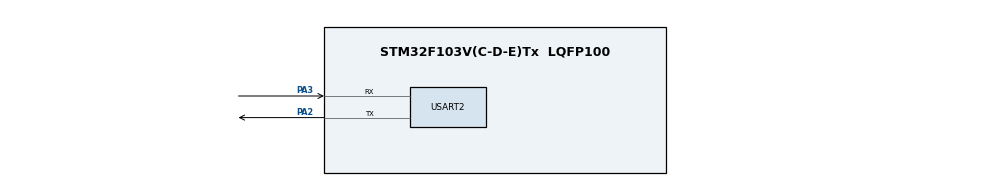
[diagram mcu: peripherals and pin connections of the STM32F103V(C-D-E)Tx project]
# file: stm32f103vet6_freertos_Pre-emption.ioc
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FREERTOS.Tasks01=defaultTask,24,128,StartDefaultTask,Default,NULL,Dynamic,NULL,NULL;LowTask,8,256,StartLowTask,Default,NULL,Dynamic,NULL,NULL;HighTask,40,256,StartHighTask,Default,NULL,Dynamic,NULL,NULL
Mcu.Family=STM32F1
Mcu.Name=STM32F103V(C-D-E)Tx
Mcu.Package=LQFP100
NVIC.PriorityGroup=NVIC_PRIORITYGROUP_4
OSC_IN.Mode=HSE-External-Oscillator
OSC_IN.Signal=RCC_OSC_IN
OSC_OUT.Mode=HSE-External-Oscillator
OSC_OUT.Signal=RCC_OSC_OUT
PA13.Mode=Serial_Wire
PA13.Signal=SYS_JTMS-SWDIO
PA14.Mode=Serial_Wire
PA14.Signal=SYS_JTCK-SWCLK
PA2.Mode=Asynchronous
PA2.Signal=USART2_TX
PA3.Mode=Asynchronous
PA3.Signal=USART2_RX
ProjectManager.HeapSize=0x200
ProjectManager.StackSize=0x400
ProjectManager.TargetToolchain=STM32CubeIDE
RCC.APB1Freq_Value=8000000
RCC.APB2Freq_Value=8000000
USART2.VirtualMode=VM_ASYNC
VP_FREERTOS_VS_CMSIS_V2.Mode=CMSIS_V2
board=custom

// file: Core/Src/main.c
/* USER CODE BEGIN Header */
/**
  ******************************************************************************
  * @file           : main.c
  * @brief          : Main program body
  ******************************************************************************
  * @attention
  *
  * Copyright (c) 2026 STMicroelectronics.
  * All rights reserved.
  *
  * This software is licensed under terms that can be found in the LICENSE file
  * in the root directory of this software component.
  * If no LICENSE file comes with this software, it is provided AS-IS.
  *
  ******************************************************************************
  */
/* USER CODE END Header */
#include "main.h"
#include "cmsis_os.h"

/* USER CODE BEGIN Includes */
#include "stdio.h"
#include "string.h"

/* USER CODE END Includes */

UART_HandleTypeDef huart2;

/* Definitions for defaultTask */
osThreadId_t defaultTaskHandle;
const osThreadAttr_t defaultTask_attributes = {
  .name = "defaultTask",
  .stack_size = 128 * 4,
  .priority = (osPriority_t) osPriorityNormal,
};
/* Definitions for LowTask */
osThreadId_t LowTaskHandle;
const osThreadAttr_t LowTask_attributes = {
  .name = "LowTask",
  .stack_size = 256 * 4,
  .priority = (osPriority_t) osPriorityLow,
};
/* Definitions for HighTask */
osThreadId_t HighTaskHandle;
const osThreadAttr_t HighTask_attributes = {
  .name = "HighTask",
  .stack_size = 256 * 4,
  .priority = (osPriority_t) osPriorityHigh,
};
/* USER CODE BEGIN PV */
volatile uint32_t countLow = 0;
volatile uint32_t countHigh = 0;

/* USER CODE END PV */

void SystemClock_Config(void);
static void MX_GPIO_Init(void);
static void MX_USART2_UART_Init(void);
void StartDefaultTask(void *argument);
void StartLowTask(void *argument);
void StartHighTask(void *argument);

int main(void)
{

  /* MCU Configuration--------------------------------------------------------*/

  /* Reset of all peripherals, Initializes the Flash interface and the Systick. */
  HAL_Init();

  /* Configure the system clock */
  SystemClock_Config();

  /* Initialize all configured peripherals */
  MX_GPIO_Init();
  MX_USART2_UART_Init();

  /* Init scheduler */
  osKernelInitialize();

  /* Create the thread(s) */
  /* creation of defaultTask */
  defaultTaskHandle = osThreadNew(StartDefaultTask, NULL, &defaultTask_attributes);

  /* creation of LowTask */
  LowTaskHandle = osThreadNew(StartLowTask, NULL, &LowTask_attributes);

  /* creation of HighTask */
  HighTaskHandle = osThreadNew(StartHighTask, NULL, &HighTask_attributes);

  /* Start scheduler */
  osKernelStart();

  /* We should never get here as control is now taken by the scheduler */

  /* Infinite loop */
  while (1)
  {

  }
}

void SystemClock_Config(void)
{
  RCC_OscInitTypeDef RCC_OscInitStruct = {0};
  RCC_ClkInitTypeDef RCC_ClkInitStruct = {0};

  /** Initializes the RCC Oscillators according to the specified parameters
  * in the RCC_OscInitTypeDef structure.
  */
  RCC_OscInitStruct.OscillatorType = RCC_OSCILLATORTYPE_HSI;
  RCC_OscInitStruct.HSIState = RCC_HSI_ON;
  RCC_OscInitStruct.HSICalibrationValue = RCC_HSICALIBRATION_DEFAULT;
  RCC_OscInitStruct.PLL.PLLState = RCC_PLL_NONE;
  if (HAL_RCC_OscConfig(&RCC_OscInitStruct) != HAL_OK)
  {
    Error_Handler();
  }

  /** Initializes the CPU, AHB and APB buses clocks
  */
  RCC_ClkInitStruct.ClockType = RCC_CLOCKTYPE_HCLK|RCC_CLOCKTYPE_SYSCLK
                              |RCC_CLOCKTYPE_PCLK1|RCC_CLOCKTYPE_PCLK2;
  RCC_ClkInitStruct.SYSCLKSource = RCC_SYSCLKSOURCE_HSI;
  RCC_ClkInitStruct.AHBCLKDivider = RCC_SYSCLK_DIV1;
  RCC_ClkInitStruct.APB1CLKDivider = RCC_HCLK_DIV1;
  RCC_ClkInitStruct.APB2CLKDivider = RCC_HCLK_DIV1;

  if (HAL_RCC_ClockConfig(&RCC_ClkInitStruct, FLASH_LATENCY_0) != HAL_OK)
  {
    Error_Handler();
  }
}

static void MX_USART2_UART_Init(void)
{

  huart2.Instance = USART2;
  huart2.Init.BaudRate = 115200;
  huart2.Init.WordLength = UART_WORDLENGTH_8B;
  huart2.Init.StopBits = UART_STOPBITS_1;
  huart2.Init.Parity = UART_PARITY_NONE;
  huart2.Init.Mode = UART_MODE_TX_RX;
  huart2.Init.HwFlowCtl = UART_HWCONTROL_NONE;
  huart2.Init.OverSampling = UART_OVERSAMPLING_16;
  if (HAL_UART_Init(&huart2) != HAL_OK)
  {
    Error_Handler();
  }

}

static void MX_GPIO_Init(void)
{

  /* GPIO Ports Clock Enable */
  __HAL_RCC_GPIOA_CLK_ENABLE();

}

void StartDefaultTask(void *argument)
{
  for(;;)
  {
    osDelay(1);
  }
}

void StartLowTask(void *argument)
{
  /* USER CODE BEGIN StartLowTask */
  /* Infinite loop */
  for(;;)
  {
	    countLow++;

  }
  /* USER CODE END StartLowTask */
}

void StartHighTask(void *argument)
{
  /* USER CODE BEGIN StartHighTask */
  /* Infinite loop */

	  osDelay(3000);

  for(;;)
  {
	    countHigh++;

  }
  /* USER CODE END StartHighTask */
}

void Error_Handler(void)
{
  __disable_irq();
  while (1)
  {
  }
}
